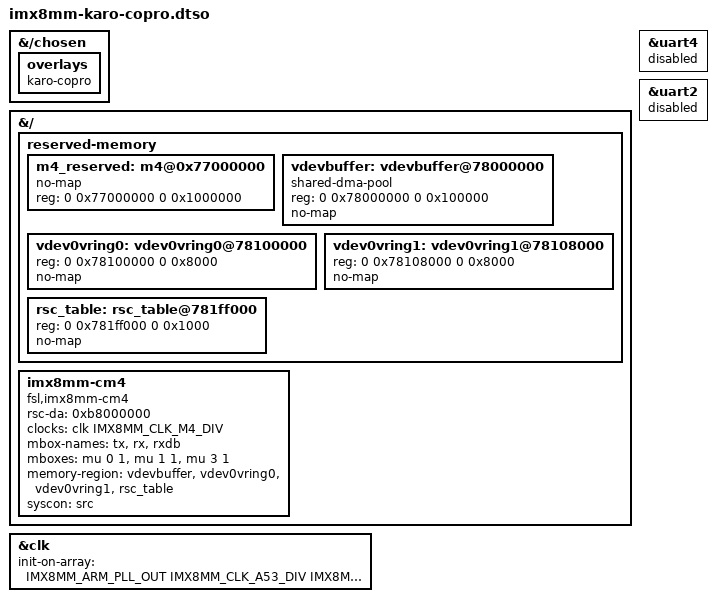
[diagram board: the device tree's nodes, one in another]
// SPDX-License-Identifier: (GPL-2.0 OR MIT)
/*
 * Copyright (C) 2023 Uwe Steinkohl <US@KARO-electronics.de>
 *
 */

#include <dt-bindings/clock/imx8mm-clock.h>

/dts-v1/;

/plugin/;

&{/chosen} {
	overlays {
		karo-copro;
	};
};

&{/} {
	reserved-memory {
		#address-cells = <2>;
		#size-cells = <2>;
		ranges;

		m4_reserved: m4@0x77000000 {
			no-map;
			reg = <0 0x77000000 0 0x1000000>;
		};

		vdevbuffer: vdevbuffer@78000000 {
			compatible = "shared-dma-pool";
			reg = <0 0x78000000 0 0x100000>;
			no-map;
		};


		vdev0vring0: vdev0vring0@78100000 {
			reg = <0 0x78100000 0 0x8000>;
			no-map;
		};

		vdev0vring1: vdev0vring1@78108000 {
			reg = <0 0x78108000 0 0x8000>;
			no-map;
		};

		rsc_table: rsc_table@781ff000 {
			reg = <0 0x781ff000 0 0x1000>;
			no-map;
		};
	};

	imx8mm-cm4 {
		compatible = "fsl,imx8mm-cm4";
		rsc-da = <0xb8000000>;
		clocks = <&clk IMX8MM_CLK_M4_DIV>;
		mbox-names = "tx", "rx", "rxdb";
		mboxes = <&mu 0 1
			  &mu 1 1
			  &mu 3 1
			 >;
		memory-region = <&vdevbuffer>, <&vdev0vring0>, <&vdev0vring1>, <&rsc_table>;
		syscon = <&src>;
	};
};

&clk {
	init-on-array = <
			 IMX8MM_ARM_PLL_OUT
			 IMX8MM_CLK_A53_DIV
			 IMX8MM_CLK_AHB
			 IMX8MM_CLK_AUDIO_AHB
			 IMX8MM_CLK_DISP_APB
			 IMX8MM_CLK_DISP_AXI
			 IMX8MM_CLK_DRAM_APB
			 IMX8MM_CLK_DRAM_CORE
			 IMX8MM_CLK_MAIN_AXI
			 IMX8MM_CLK_NOC
			 IMX8MM_CLK_NOC_APB
			 IMX8MM_CLK_UART4_ROOT
			 IMX8MM_CLK_USB_BUS
			>;
};

/*
 * ATTENTION: M4 may use IPs like below
 * ECSPI0/ECSPI2, GPIO1/GPIO5, GPT1, I2C3, I2S3, WDOG1, UART4, PWM3, SDMA1
 */
&uart4 {
	status = "disabled";
};

&uart2 {
	status = "disabled";
};
